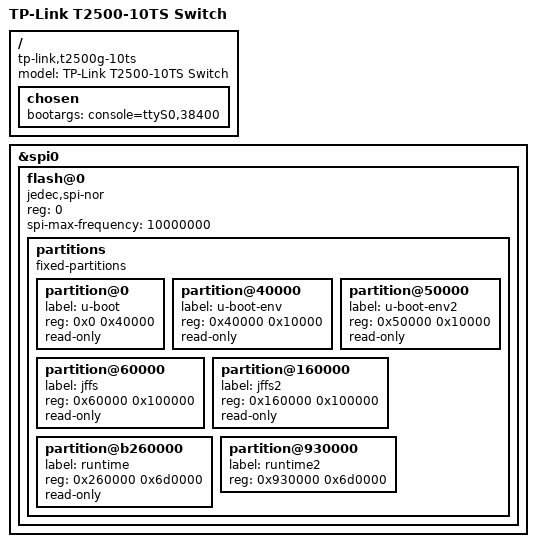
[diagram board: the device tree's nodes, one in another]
/dts-v1/;


#include <dt-bindings/input/input.h>
#include "rtl838x.dtsi"

/ {
	compatible = "tp-link,t2500g-10ts", "realtek,rtl838x-soc";
	model = "TP-Link T2500-10TS Switch";
/*
	aliases {
		led-boot = &led_status_yellow;
		led-failsafe = &led_status_red;
		led-running = &led_status_blue;
		led-upgrade = &led_status_yellow;
	};
*/
	chosen {
		bootargs = "console=ttyS0,38400";
	};
};

&spi0 {

	status = "okay";
        flash@0 {
                compatible = "jedec,spi-nor";
                reg = <0>;
                spi-max-frequency = <10000000>;

                partitions {
                        compatible = "fixed-partitions";
                        #address-cells = <1>;
                        #size-cells = <1>;

                        partition@0 {
                                label = "u-boot";
                                reg = <0x0 0x40000>;
                                read-only;
                        };
                        partition@40000 {
                                label = "u-boot-env";
                                reg = <0x40000 0x10000>;
                                read-only;
                        };
                        partition@50000 {
                                label = "u-boot-env2";
                                reg = <0x50000 0x10000>;
                                read-only;
                        };
                        partition@60000 {
                                label = "jffs";
                                reg = <0x60000 0x100000>;
                                read-only;
                        };
                        partition@160000 {
                                label = "jffs2";
                                reg = <0x160000 0x100000>;
                                read-only;
                        };
                        partition@b260000 {
                                label = "runtime";
                                reg = <0x260000 0x6d0000>;
                                read-only;
                        };
                        partition@930000 {
                                label = "runtime2";
                                reg = <0x930000 0x6d0000>;
                        };
		};
	};
};
